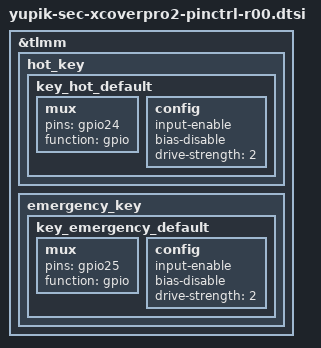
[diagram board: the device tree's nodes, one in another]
/* Copyright (c) 2021, The Linux Foundation. All rights reserved.
 *
 * This program is free software; you can redistribute it and/or modify
 * it under the terms of the GNU General Public License version 2 and
 * only version 2 as published by the Free Software Foundation.
 *
 * This program is distributed in the hope that it will be useful,
 * but WITHOUT ANY WARRANTY; without even the implied warranty of
 * MERCHANTABILITY or FITNESS FOR A PARTICULAR PURPOSE.  See the
 * GNU General Public License for more details.
 */
 
#include "yupik-sec-xcoverpro2-camera-sensor-pinctrl-common.dtsi"

&tlmm {
	hot_key {
		key_hot_default: key_hot_default {
			mux {
				pins = "gpio24";
				function = "gpio";
			};
			config {
				input-enable;
				bias-disable;
				drive-strength = <2>;
			};
		};
	};

	emergency_key {
		key_emergency_default: key_emergency_default {
			mux {
				pins = "gpio25";
				function = "gpio";
			};
			config {
				input-enable;
				bias-disable;
				drive-strength = <2>;
			};
		};
	};
};


